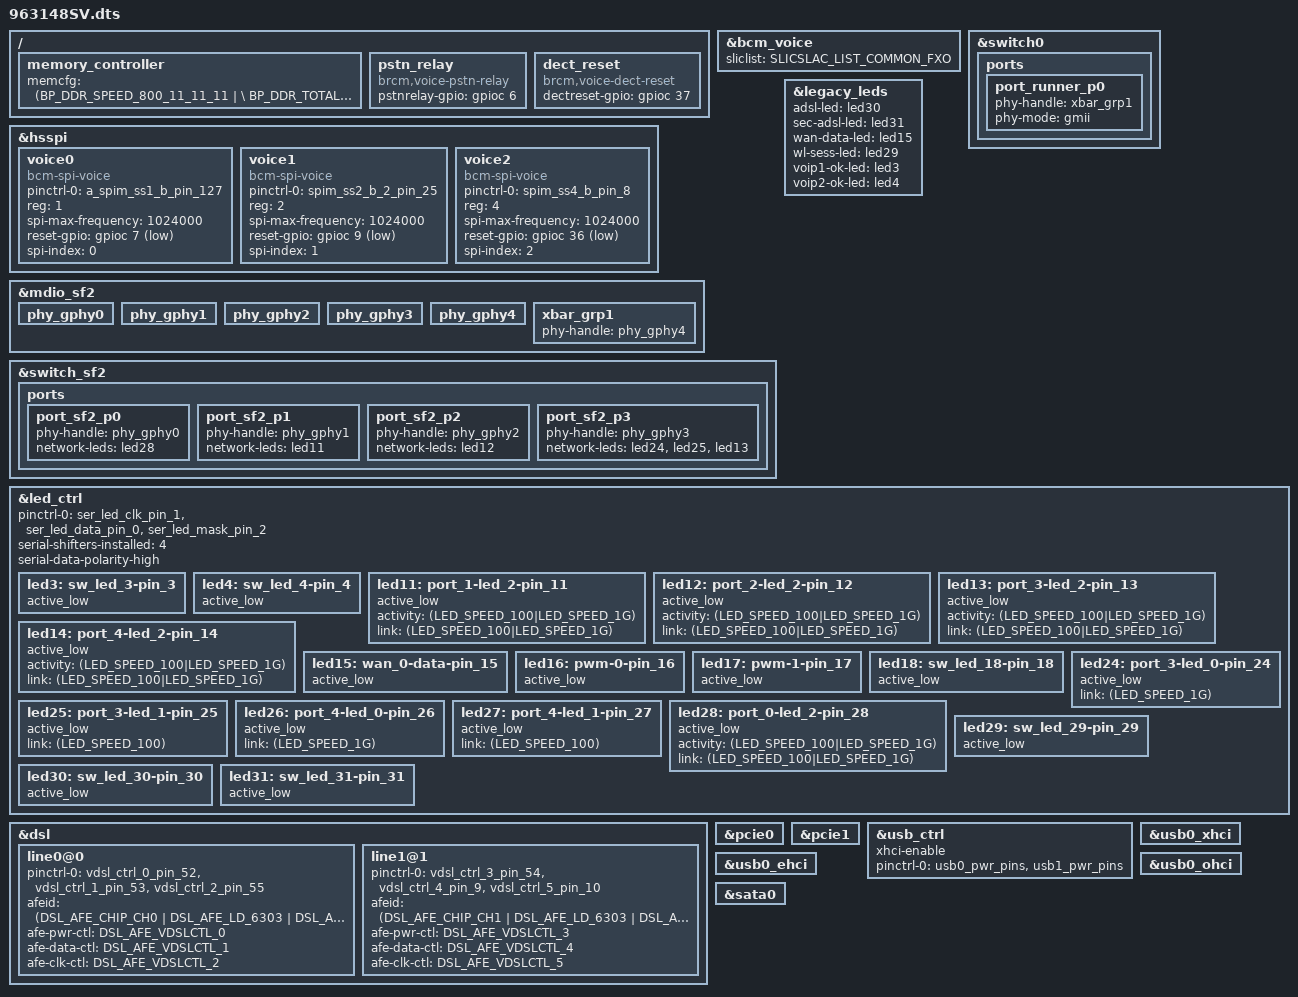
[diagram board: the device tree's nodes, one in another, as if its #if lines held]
#include "63148.dtsi"
#include "../bcm_voice.dtsi"

/ {
	memory_controller {
		memcfg = <(BP_DDR_SPEED_800_11_11_11 | \
				BP_DDR_TOTAL_SIZE_1024MB  | \
				BP_DDR_DEVICE_WIDTH_8)>;
	};

	pstn_relay:pstn_relay {
		compatible = "brcm,voice-pstn-relay";
		pstnrelay-gpio = <&gpioc 6 GPIO_ACTIVE_HIGH>;
	};

	dect_reset:dect_reset {
		compatible = "brcm,voice-dect-reset";
		dectreset-gpio = <&gpioc 37 GPIO_ACTIVE_HIGH>;
	};
};

&bcm_voice{
	sliclist = SLICSLAC_LIST_COMMON_FXO;
 };

&hsspi {
	status = "okay";
	voice0 {
		pinctrl-0 = <&a_spim_ss1_b_pin_127>;
		pinctrl-names = "default";
		compatible = "bcm-spi-voice";
		reg = <1>; /* chip select 1 */
		spi-max-frequency = <1024000>;
		reset-gpio = <&gpioc 7 GPIO_ACTIVE_LOW>;
		spi-index = <0>;/* voice header index */
	};
	voice1 {
		pinctrl-0 = <&spim_ss2_b_2_pin_25>;
		pinctrl-names = "default";
		compatible = "bcm-spi-voice";
		reg = <2>; /* chip select 2 */
		spi-max-frequency = <1024000>;
		reset-gpio = <&gpioc 9 GPIO_ACTIVE_LOW>;
		spi-index = <1>;/* voice header index */
	};
	voice2 {
		pinctrl-0 = <&spim_ss4_b_pin_8>;
		pinctrl-names = "default";
		compatible = "bcm-spi-voice";
		reg = <4>; /* chip select 2 */
		spi-max-frequency = <1024000>;
		reset-gpio = <&gpioc 36 GPIO_ACTIVE_LOW>;
		spi-index = <2>;/* voice header index */
	};
};



&mdio_sf2 {
        /* Port PHY mapping:
            port_runner_p1  <-->  port_sf2_p8 -###- port_sf2_p0 <------------------> phy_gphy0
                                               # #- port_sf2_p1 <------------------> phy_gphy1
                                               # #- port_sf2_p2 <------------------> phy_gphy2
                                               ###- port_sf2_p3 <------------------> phy_gphy3
                                                 port_runner_p0 <--> xbar_grp1 -+-+- phy_gphy4
         */
	/* PHYs directly connected to SF2 */
	phy_gphy0 {
		status = "okay";
	};
	phy_gphy1 {
		status = "okay";
	};
	phy_gphy2 {
		status = "okay";
	};
	phy_gphy3 {
		status = "okay";
	};

	/* PHYs connected to crossbar */
	phy_gphy4 {
		status = "okay";
	};

	/* Crossbar groups */
	xbar_grp1 {
		phy-handle = <&phy_gphy4>;
		status = "okay";
	};
};

&switch_sf2 {
	ports {
		port_sf2_p0 {
			phy-handle = <&phy_gphy0>;
			/* link led use wrong gpio pin in the board design for port 0, 1, 2.
			   Use activity to show both link/activity */
			network-leds = <&led28>;
			status = "okay";
		};

		port_sf2_p1 {
			phy-handle = <&phy_gphy1>;
			network-leds = <&led11>;
			status = "okay";
		};

		port_sf2_p2 {
			phy-handle = <&phy_gphy2>;
			network-leds = <&led12>;
			status = "okay";
		};

		port_sf2_p3 {
			phy-handle = <&phy_gphy3>;
			network-leds = <&led24 &led25 &led13>;
			status = "okay";
		};

	};
};

&switch0 {
	ports {
		
		port_runner_p0 {
			phy-handle = <&xbar_grp1>;
			phy-mode = "gmii";
			status = "okay";
		};
	};
};


&legacy_leds {
	adsl-led = <&led30>;
	sec-adsl-led = <&led31>;
	wan-data-led = <&led15>;
	wl-sess-led = <&led29>;
	voip1-ok-led = <&led3>;
	voip2-ok-led = <&led4>;
};

&led_ctrl {
	pinctrl-names = "default";
	pinctrl-0 = <&ser_led_clk_pin_1 &ser_led_data_pin_0 &ser_led_mask_pin_2>;
	serial-shifters-installed = <4>;
	serial-data-polarity-high;

	led3: sw_led_3-pin_3 {
		active_low;
		status = "okay";
	};
	led4: sw_led_4-pin_4 {
		active_low;
		status = "okay";
	};
	led11: port_1-led_2-pin_11 {
		active_low;
		activity = <(LED_SPEED_100|LED_SPEED_1G)>;
		link = <(LED_SPEED_100|LED_SPEED_1G)>;
		status = "okay";
	};
	led12: port_2-led_2-pin_12 {
		active_low;
		activity = <(LED_SPEED_100|LED_SPEED_1G)>;
		link = <(LED_SPEED_100|LED_SPEED_1G)>;
		status = "okay";
	};
	led13: port_3-led_2-pin_13 {
		active_low;
		activity = <(LED_SPEED_100|LED_SPEED_1G)>;
		link = <(LED_SPEED_100|LED_SPEED_1G)>;		
		status = "okay";
	};
	led14: port_4-led_2-pin_14 {
		active_low;
		activity = <(LED_SPEED_100|LED_SPEED_1G)>;
		link = <(LED_SPEED_100|LED_SPEED_1G)>;
		status = "okay";
	};
	led15: wan_0-data-pin_15 {
		active_low;
		status = "okay";
	};
	led16: pwm-0-pin_16 {
		active_low;
		status = "okay";
	};
	led17: pwm-1-pin_17 {
		active_low;
		status = "okay";
	};
	led18: sw_led_18-pin_18 {
		active_low;
		status = "okay";
	};
	led24: port_3-led_0-pin_24 {
		active_low;
		link = <(LED_SPEED_1G)>;
		status = "okay";
	};
	led25: port_3-led_1-pin_25 {
		active_low;
		link = <(LED_SPEED_100)>;
		status = "okay";
	};
	led26: port_4-led_0-pin_26 {
		active_low;
		link = <(LED_SPEED_1G)>;
		status = "okay";
	};
	led27: port_4-led_1-pin_27 {
		active_low;
		link = <(LED_SPEED_100)>;
		status = "okay";
	};
	led28: port_0-led_2-pin_28 {
		active_low;
		activity = <(LED_SPEED_100|LED_SPEED_1G)>;
		link = <(LED_SPEED_100|LED_SPEED_1G)>;
		status = "okay";
	};
	led29: sw_led_29-pin_29 {
		active_low;
		status = "okay";
	};
	led30: sw_led_30-pin_30 {
		active_low;
		status = "okay";
	};
	led31: sw_led_31-pin_31 {
		active_low;
		status = "okay";
	};
};

&dsl {
	line0@0 {
		pinctrl-0 = <&vdsl_ctrl_0_pin_52 &vdsl_ctrl_1_pin_53 &vdsl_ctrl_2_pin_55>;
		pinctrl-names = "default";

		afeid = <(DSL_AFE_CHIP_CH0 | DSL_AFE_LD_6303 | DSL_AFE_FE_ANNEXA | DSL_AFE_FE_REV_6303_REV_12_3_40)>;
		afe-pwr-ctl = <DSL_AFE_VDSLCTL_0>;
		afe-data-ctl = <DSL_AFE_VDSLCTL_1>;
		afe-clk-ctl = <DSL_AFE_VDSLCTL_2>;
		status = "okay";
	};

	line1@1 {
		pinctrl-0 = <&vdsl_ctrl_3_pin_54 &vdsl_ctrl_4_pin_9 &vdsl_ctrl_5_pin_10>;
		pinctrl-names = "default";

		afeid = <(DSL_AFE_CHIP_CH1 | DSL_AFE_LD_6303 | DSL_AFE_FE_ANNEXA | DSL_AFE_FE_REV_6303_REV_12_3_40)>;
		afe-pwr-ctl = <DSL_AFE_VDSLCTL_3>;
		afe-data-ctl = <DSL_AFE_VDSLCTL_4>;
		afe-clk-ctl = <DSL_AFE_VDSLCTL_5>;
		status = "okay";
	};
};

#if defined(CONFIG_BCM_PCIE_HCD) || defined(CONFIG_BCM_PCIE_HCD_MODULE)
&pcie0 {
	status = "okay";
};
&pcie1 {
	status = "okay";
};
#endif //#if defined(CONFIG_BCM_PCIE_HCD) || defined(CONFIG_BCM_PCIE_HCD_MODULE)

&usb_ctrl {
	status = "okay";
	xhci-enable;
	pinctrl-names = "default";
	pinctrl-0 = <&usb0_pwr_pins &usb1_pwr_pins>;
};

&usb0_xhci {
	status = "okay";
};

&usb0_ehci {
	status = "okay";
};

&usb0_ohci {
	status = "okay";
};

&sata0 {
	status = "okay";
};
